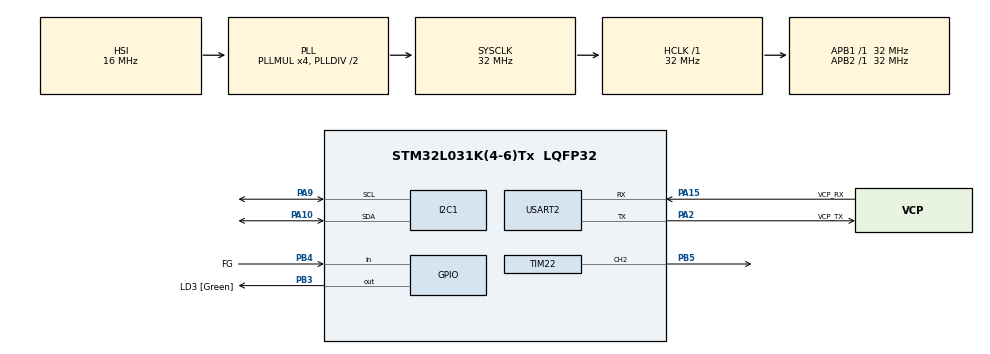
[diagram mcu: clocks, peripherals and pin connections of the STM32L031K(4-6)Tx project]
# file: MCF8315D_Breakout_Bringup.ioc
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I2C1.Speed=10
I2C1.Timing=0x801062FE
Mcu.Family=STM32L0
Mcu.Name=STM32L031K(4-6)Tx
Mcu.Package=LQFP32
NVIC.I2C1_IRQn=true\:0\:0\:false\:false\:true\:true\:true\:true
PA10.Mode=I2C
PA10.Signal=I2C1_SDA
PA13.GPIO_Label=TMS
PA13.Mode=Serial_Wire
PA13.Signal=SYS_SWDIO
PA14.GPIO_Label=TCK
PA14.Mode=Serial_Wire
PA14.Signal=SYS_SWCLK
PA15.GPIO_Label=VCP_RX
PA15.Mode=Asynchronous
PA15.Signal=USART2_RX
PA2.GPIO_Label=VCP_TX
PA2.Mode=Asynchronous
PA2.Signal=USART2_TX
PA9.Mode=I2C
PA9.Signal=I2C1_SCL
PB3.GPIO_Label=LD3 [Green]
PB3.Signal=GPIO_Output
PB4.GPIO_Label=FG
PB4.Signal=GPIO_Input
PB5.Signal=S_TIM22_CH2
PC14-OSC32_IN.Mode=LSE-External-Oscillator
PC14-OSC32_IN.Signal=RCC_OSC32_IN
PC15-OSC32_OUT.Mode=LSE-External-Oscillator
PC15-OSC32_OUT.Signal=RCC_OSC32_OUT
ProjectManager.HeapSize=0x200
ProjectManager.StackSize=0x400
ProjectManager.TargetToolchain=CMake
RCC.AHBFreq_Value=32000000
RCC.APB1Freq_Value=32000000
RCC.APB1TimFreq_Value=32000000
RCC.APB2Freq_Value=32000000
RCC.APB2TimFreq_Value=32000000
RCC.HCLKFreq_Value=32000000
RCC.HSE_VALUE=8000000
RCC.HSI16_VALUE=16000000
RCC.HSI48_VALUE=48000000
RCC.HSI_VALUE=16000000
RCC.MSI_VALUE=2097000
RCC.PLLMUL=RCC_PLLMUL_4
RCC.SYSCLKFreq_VALUE=32000000
RCC.SYSCLKSource=RCC_SYSCLKSOURCE_PLLCLK
RCC.VCOOutputFreq_Value=64000000
SH.S_TIM22_CH2.0=TIM22_CH2,PWM Generation2 CH2
TIM22.Channel-PWM\ Generation2\ CH2=TIM_CHANNEL_2
TIM22.CounterMode=TIM_COUNTERMODE_UP
TIM22.Period=100-1
TIM22.Prescaler=1000-1
USART2.VirtualMode-Asynchronous=VM_ASYNC
board=NUCLEO-L031K6

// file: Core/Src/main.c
/* USER CODE BEGIN Header */
/**
  ******************************************************************************
  * @file           : main.c
  * @brief          : Main program body
  ******************************************************************************
  * @attention
  *
  * Copyright (c) 2026 STMicroelectronics.
  * All rights reserved.
  *
  * This software is licensed under terms that can be found in the LICENSE file
  * in the root directory of this software component.
  * If no LICENSE file comes with this software, it is provided AS-IS.
  *
  ******************************************************************************
  */
/* USER CODE END Header */
#include "main.h"

/* USER CODE BEGIN Includes */
#include "MCF8315D.h"
/* USER CODE END Includes */

I2C_HandleTypeDef hi2c1;

TIM_HandleTypeDef htim22;

UART_HandleTypeDef huart2;

void SystemClock_Config(void);
static void MX_GPIO_Init(void);
static void MX_I2C1_Init(void);
static void MX_USART2_UART_Init(void);
static void MX_TIM22_Init(void);

int main(void)
{

  /* MCU Configuration--------------------------------------------------------*/

  /* Reset of all peripherals, Initializes the Flash interface and the Systick. */
  HAL_Init();

  /* Configure the system clock */
  SystemClock_Config();

  /* Initialize all configured peripherals */
  MX_GPIO_Init();
  MX_I2C1_Init();
  MX_USART2_UART_Init();
  MX_TIM22_Init();
  /* USER CODE BEGIN 2 */
  MCF8315_init(&hi2c1);
  /* USER CODE END 2 */

  /* Infinite loop */
  while (1)
  {

  }
}

void SystemClock_Config(void)
{
  RCC_OscInitTypeDef RCC_OscInitStruct = {0};
  RCC_ClkInitTypeDef RCC_ClkInitStruct = {0};
  RCC_PeriphCLKInitTypeDef PeriphClkInit = {0};

  /** Configure the main internal regulator output voltage
  */
  __HAL_PWR_VOLTAGESCALING_CONFIG(PWR_REGULATOR_VOLTAGE_SCALE1);

  /** Initializes the RCC Oscillators according to the specified parameters
  * in the RCC_OscInitTypeDef structure.
  */
  RCC_OscInitStruct.OscillatorType = RCC_OSCILLATORTYPE_HSI;
  RCC_OscInitStruct.HSIState = RCC_HSI_ON;
  RCC_OscInitStruct.HSICalibrationValue = RCC_HSICALIBRATION_DEFAULT;
  RCC_OscInitStruct.PLL.PLLState = RCC_PLL_ON;
  RCC_OscInitStruct.PLL.PLLSource = RCC_PLLSOURCE_HSI;
  RCC_OscInitStruct.PLL.PLLMUL = RCC_PLLMUL_4;
  RCC_OscInitStruct.PLL.PLLDIV = RCC_PLLDIV_2;
  if (HAL_RCC_OscConfig(&RCC_OscInitStruct) != HAL_OK)
  {
    Error_Handler();
  }

  /** Initializes the CPU, AHB and APB buses clocks
  */
  RCC_ClkInitStruct.ClockType = RCC_CLOCKTYPE_HCLK|RCC_CLOCKTYPE_SYSCLK
                              |RCC_CLOCKTYPE_PCLK1|RCC_CLOCKTYPE_PCLK2;
  RCC_ClkInitStruct.SYSCLKSource = RCC_SYSCLKSOURCE_PLLCLK;
  RCC_ClkInitStruct.AHBCLKDivider = RCC_SYSCLK_DIV1;
  RCC_ClkInitStruct.APB1CLKDivider = RCC_HCLK_DIV1;
  RCC_ClkInitStruct.APB2CLKDivider = RCC_HCLK_DIV1;

  if (HAL_RCC_ClockConfig(&RCC_ClkInitStruct, FLASH_LATENCY_1) != HAL_OK)
  {
    Error_Handler();
  }
  PeriphClkInit.PeriphClockSelection = RCC_PERIPHCLK_USART2|RCC_PERIPHCLK_I2C1;
  PeriphClkInit.Usart2ClockSelection = RCC_USART2CLKSOURCE_PCLK1;
  PeriphClkInit.I2c1ClockSelection = RCC_I2C1CLKSOURCE_PCLK1;
  if (HAL_RCCEx_PeriphCLKConfig(&PeriphClkInit) != HAL_OK)
  {
    Error_Handler();
  }
}

static void MX_I2C1_Init(void)
{

  hi2c1.Instance = I2C1;
  hi2c1.Init.Timing = 0x801062FE;
  hi2c1.Init.OwnAddress1 = 0;
  hi2c1.Init.AddressingMode = I2C_ADDRESSINGMODE_7BIT;
  hi2c1.Init.DualAddressMode = I2C_DUALADDRESS_DISABLE;
  hi2c1.Init.OwnAddress2 = 0;
  hi2c1.Init.OwnAddress2Masks = I2C_OA2_NOMASK;
  hi2c1.Init.GeneralCallMode = I2C_GENERALCALL_DISABLE;
  hi2c1.Init.NoStretchMode = I2C_NOSTRETCH_DISABLE;
  if (HAL_I2C_Init(&hi2c1) != HAL_OK)
  {
    Error_Handler();
  }

  /** Configure Analogue filter
  */
  if (HAL_I2CEx_ConfigAnalogFilter(&hi2c1, I2C_ANALOGFILTER_ENABLE) != HAL_OK)
  {
    Error_Handler();
  }

  /** Configure Digital filter
  */
  if (HAL_I2CEx_ConfigDigitalFilter(&hi2c1, 0) != HAL_OK)
  {
    Error_Handler();
  }

}

static void MX_TIM22_Init(void)
{

  TIM_MasterConfigTypeDef sMasterConfig = {0};
  TIM_OC_InitTypeDef sConfigOC = {0};

  htim22.Instance = TIM22;
  htim22.Init.Prescaler = 1000-1;
  htim22.Init.CounterMode = TIM_COUNTERMODE_UP;
  htim22.Init.Period = 100-1;
  htim22.Init.ClockDivision = TIM_CLOCKDIVISION_DIV1;
  htim22.Init.AutoReloadPreload = TIM_AUTORELOAD_PRELOAD_DISABLE;
  if (HAL_TIM_PWM_Init(&htim22) != HAL_OK)
  {
    Error_Handler();
  }
  sMasterConfig.MasterOutputTrigger = TIM_TRGO_RESET;
  sMasterConfig.MasterSlaveMode = TIM_MASTERSLAVEMODE_DISABLE;
  if (HAL_TIMEx_MasterConfigSynchronization(&htim22, &sMasterConfig) != HAL_OK)
  {
    Error_Handler();
  }
  sConfigOC.OCMode = TIM_OCMODE_PWM1;
  sConfigOC.Pulse = 0;
  sConfigOC.OCPolarity = TIM_OCPOLARITY_HIGH;
  sConfigOC.OCFastMode = TIM_OCFAST_DISABLE;
  if (HAL_TIM_PWM_ConfigChannel(&htim22, &sConfigOC, TIM_CHANNEL_2) != HAL_OK)
  {
    Error_Handler();
  }
  HAL_TIM_MspPostInit(&htim22);

}

static void MX_USART2_UART_Init(void)
{

  huart2.Instance = USART2;
  huart2.Init.BaudRate = 115200;
  huart2.Init.WordLength = UART_WORDLENGTH_8B;
  huart2.Init.StopBits = UART_STOPBITS_1;
  huart2.Init.Parity = UART_PARITY_NONE;
  huart2.Init.Mode = UART_MODE_TX_RX;
  huart2.Init.HwFlowCtl = UART_HWCONTROL_NONE;
  huart2.Init.OverSampling = UART_OVERSAMPLING_16;
  huart2.Init.OneBitSampling = UART_ONE_BIT_SAMPLE_DISABLE;
  huart2.AdvancedInit.AdvFeatureInit = UART_ADVFEATURE_NO_INIT;
  if (HAL_UART_Init(&huart2) != HAL_OK)
  {
    Error_Handler();
  }

}

static void MX_GPIO_Init(void)
{
  GPIO_InitTypeDef GPIO_InitStruct = {0};

  /* GPIO Ports Clock Enable */
  __HAL_RCC_GPIOC_CLK_ENABLE();
  __HAL_RCC_GPIOA_CLK_ENABLE();
  __HAL_RCC_GPIOB_CLK_ENABLE();

  /*Configure GPIO pin Output Level */
  HAL_GPIO_WritePin(LD3_GPIO_Port, LD3_Pin, GPIO_PIN_RESET);

  /*Configure GPIO pin : LD3_Pin */
  GPIO_InitStruct.Pin = LD3_Pin;
  GPIO_InitStruct.Mode = GPIO_MODE_OUTPUT_PP;
  GPIO_InitStruct.Pull = GPIO_NOPULL;
  GPIO_InitStruct.Speed = GPIO_SPEED_FREQ_LOW;
  HAL_GPIO_Init(LD3_GPIO_Port, &GPIO_InitStruct);

  /*Configure GPIO pin : FG_Pin */
  GPIO_InitStruct.Pin = FG_Pin;
  GPIO_InitStruct.Mode = GPIO_MODE_INPUT;
  GPIO_InitStruct.Pull = GPIO_NOPULL;
  HAL_GPIO_Init(FG_GPIO_Port, &GPIO_InitStruct);

}

void Error_Handler(void)
{
  __disable_irq();
  while (1)
  {
  }
}
